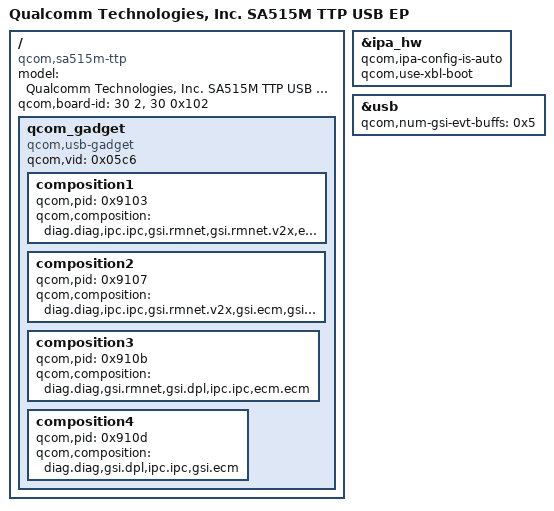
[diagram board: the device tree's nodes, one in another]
/* Copyright (c) 2019-2020, The Linux Foundation. All rights reserved.
 *
 * This program is free software; you can redistribute it and/or modify
 * it under the terms of the GNU General Public License version 2 and
 * only version 2 as published by the Free Software Foundation.
 *
 * This program is distributed in the hope that it will be useful,
 * but WITHOUT ANY WARRANTY; without even the implied warranty of
 * MERCHANTABILITY or FITNESS FOR A PARTICULAR PURPOSE.  See the
 * GNU General Public License for more details.
 */

/dts-v1/;

#include "sa515m-v2-ttp.dtsi"

/ {
	model = "Qualcomm Technologies, Inc. SA515M TTP USB EP";
	compatible = "qcom,sa515m-ttp",
		"qcom,sdxprairie","qcom,ttp";
	qcom,board-id = <30 2> , <30 0x102>;

	/delete-node/ qcom_gadget;
	qcom_gadget {
		compatible = "qcom,usb-gadget";
		qcom,vid = <0x05c6>;

		composition1 {
			qcom,pid = <0x9103>;
			qcom,composition = "diag.diag,ipc.ipc,gsi.rmnet,gsi.rmnet.v2x,ecm.ecm,gsi.dpl";
		};

		composition2 {
			qcom,pid = <0x9107>;
			qcom,composition = "diag.diag,ipc.ipc,gsi.rmnet.v2x,gsi.ecm,gsi.dpl";
		};

		composition3 {
			qcom,pid = <0x910b>;
			qcom,composition = "diag.diag,gsi.rmnet,gsi.dpl,ipc.ipc,ecm.ecm";
		};

		composition4 {
			qcom,pid = <0x910d>;
			qcom,composition = "diag.diag,gsi.dpl,ipc.ipc,gsi.ecm";
		};
	};
};

&ipa_hw {
	qcom,ipa-config-is-auto;
	qcom,use-xbl-boot;
};

&usb {
	qcom,num-gsi-evt-buffs = <0x5>;
};
